# LKS32MC07x register map
Vendor: Linko Ltd.; Series: LKS32MC07x; File version: 1.0
CPU: CM0 r1p0, little endian, MPU, no FPU, 3 interrupt priority bits
Registers are 32-bit, read-write, reset 0x0 unless marked. A register's access mark holds for its fields unless they carry their own. Offsets are from the block's base; [hi:lo] are bit positions; {n}, {i} and the like mark numbered series.

## DSP0 — DSP0 registers
Base 0x40012000
0xFF8 OP — DSP oprand which could be accessed during DSP is running
  [15:0] OPRAND
0xFFC RES — DSP result which could be accessed during DSP is running
  [15:0] RESULT
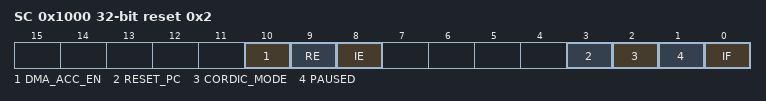
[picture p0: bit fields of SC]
0x1000 SC reset 0x2 — DSP control and status
  [10] DMA_ACC_EN — DMA access enable
  [9] RE — DMA request enable
  [8] IE — Interrupt enable
  [3] RESET_PC wo — Reset DSP PC
  [2] CORDIC_MODE — SINCOS/ARCTAN
    0=ARCTAN (ARCTAN mode); 1=SIN_COS (SIN_COS mode)
  [1] PAUSED — DSP paused
  [0] IF — DSP IRQ flag, write 1 to clear
0x1004 THETA — Theta for cordic
  [15:0] THETA
0x1008 X — Coordinate X for arctan
  [15:0] X
0x100C Y — Coordinate Y for arctan
  [15:0] Y
0x1010 SIN ro — SIN result
  [15:0] SIN
0x1014 COS ro — COS result
  [15:0] COS
0x1018 MOD ro — MOD result
  [15:0] MOD
0x101C ARCTAN ro — ARCTAN result
  [15:0] ARCTAN
0x1020 DID — DSP dividend
0x1024 DIS — DSP divider
0x1028 QUO ro — DSP quotient
0x102C REM ro — DSP remainder
0x1030 RAD — DSP radicand
0x1034 SQRT 16-bit ro — DSP square root
0x1038 PC — DSP Program Counter
  [8:0] PC

## IWDG — IWDG registers
Base 0x40011700
0x00 PSW 16-bit wo — IWDG password
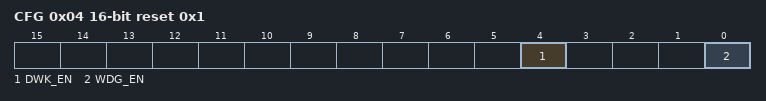
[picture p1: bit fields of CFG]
0x04 CFG 16-bit reset 0x1 — IWDG configuration
  [4] DWK_EN — Deep wakeup enable
    0=DISABLED (IWDG deep wakeup signal is disabled); 1=ENABLED (IWDG deep wakeup signal is enabled)
  [0] WDG_EN — IWDG enable
    0=DISABLED (IWDG is disabled); 1=ENABLED (IWDG is enabled)
0x08 CLR wo — IWDG counter clear
  [15:0] PSW — Counter clear password
0x0C WTH — IWDG wakeup threshold
  [20:12] WTH — IWDG wakeup theshold
0x10 RTH — IWDG reset threshold
  [20:12] RTH — IWDG bite theshold
0x14 CNT ro — IWDG counter
  [20:0] CNT — IWDG counter value

## AON — AON registers
Base 0x40011720
0x00 PWR_CFG — power management configure
  [1] IOWK_FLT — IO wakeup filter enable
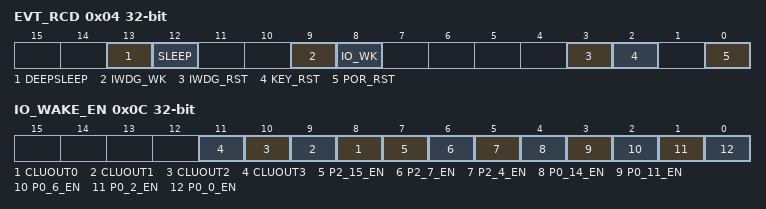
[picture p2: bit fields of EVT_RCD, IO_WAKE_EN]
0x04 EVT_RCD — Event record
  [13] DEEPSLEEP ro — Deep sleep record
  [12] SLEEP ro — Sleep record
  [9] IWDG_WK ro — IWDG wakeup record
  [8] IO_WK ro — IO wakeup record
  [3] IWDG_RST ro — IWDG reset record
  [2] KEY_RST ro — Key reset record
  [0] POR_RST ro — POR record
0x08 IO_WAKE_POL — IO wakeup signal polarity
  [0] WK_POL — Wakeup signal polarity
0x0C IO_WAKE_EN (reset mask 0xFF) — IO wakeup enable
  [n+8] CLUOUT{n} (n=0..3) — CLUOUT{n} wakeup enable
  [7] P2_15_EN — P2.15 wakeup enable
  [6] P2_7_EN — P2.7 wakeup enable
  [5] P2_4_EN — P2.4 wakeup enable
  [4] P0_14_EN — P0.14 wakeup enable
  [3] P0_11_EN — P0.11 wakeup enable
  [2] P0_6_EN — P0.6 wakeup enable
  [1] P0_2_EN — P0.2 wakeup enable
  [0] P0_0_EN — P0.0 wakeup enable

## CL0 — CL0 registers
Base 0x40011800
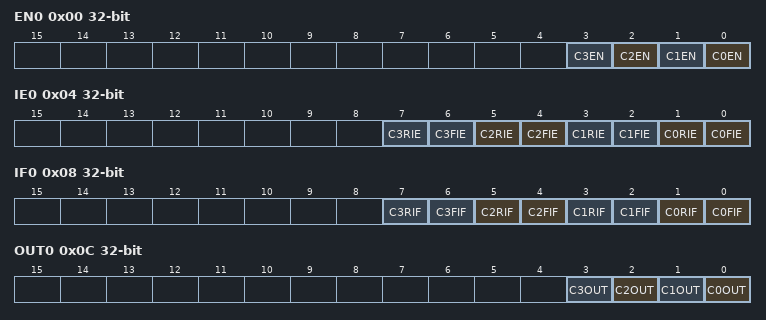
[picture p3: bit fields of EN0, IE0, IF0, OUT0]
0x00 EN0 — CL0 Enable
  [all] fields
    0=DISABLED (CLU is disabled); 1=ENABLED (CLU is enabled)
  [n] C{n}EN (n=0..3) — CLU{n} Enable
0x04 IE0 — CL0 Interrupt Enable
  [2n+1] C{n}RIE (n=0..3) — CLU{n} Rising Edge Interrupt Enable
    0=DISABLED (CLU Rising Edge Interrupt is disabled); 1=ENABLED (CLU Rising Edge Interrupt is enabled)
  [2n] C{n}FIE (n=0..3) — CLU{n} Falling Edge Interrupt Enable
    0=DISABLED (CLU Falling Edge Interrupt is disabled); 1=ENABLED (CLU Falling Edge Interrupt is enabled)
0x08 IF0 — CL0 Interrupt Flag
  [2n+1] C{n}RIF (n=0..3) — CLU{n} Rising Edge Interrupt Flag
    0=CLEAR (CLU Rising Edge Interrupt is Clear); 1=SET (CLU Rising Edge Interrupt is Set)
  [2n] C{n}FIF (n=0..3) — CLU{n} Falling Edge Interrupt Flag
    0=CLEAR (CLU Falling Edge Interrupt is Clear); 1=SET (CLU Falling Edge Interrupt is Set)
0x0C OUT0 — CL0 Output Register
  [n] C{n}OUT ro (n=0..3) — CLU{n} Output State
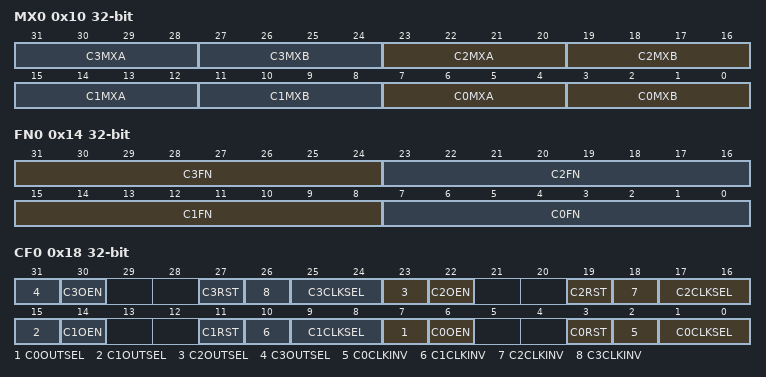
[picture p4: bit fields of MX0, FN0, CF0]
0x10 MX0 — CL0 Multiplex Selection Register
  [8n+7:8n+4] C{n}MXA (n=0..3) — CLU{n} A Input Multiplex Selection
  [8n+3:8n] C{n}MXB (n=0..3) — CLU{n} B Input Multiplex Selection
0x14 FN0 — CL0 Function Selection Register
  [31:24] C3FN — CLU3 Function Selection
  [23:16] C2FN — CLU3 Function Selection
  [15:8] C1FN — CLU2 Function Selection
  [7:0] C0FN — CLU2 Function Selection
0x18 CF0 — CL0 Configure Register
  [8n+7] C{n}OUTSEL (n=0..3) — CLU Output Selection
  [8n+6] C{n}OEN (n=0..3) — CLU Output Enable
  [8n+3] C{n}RST (n=0..3) — CLU DFF Reset
  [8n+2] C{n}CLKINV (n=0..3) — CLU DFF Clock Reverse
  [8n+1:8n] C{n}CLKSEL (n=0..3) — CLU DFF Clock Selection
